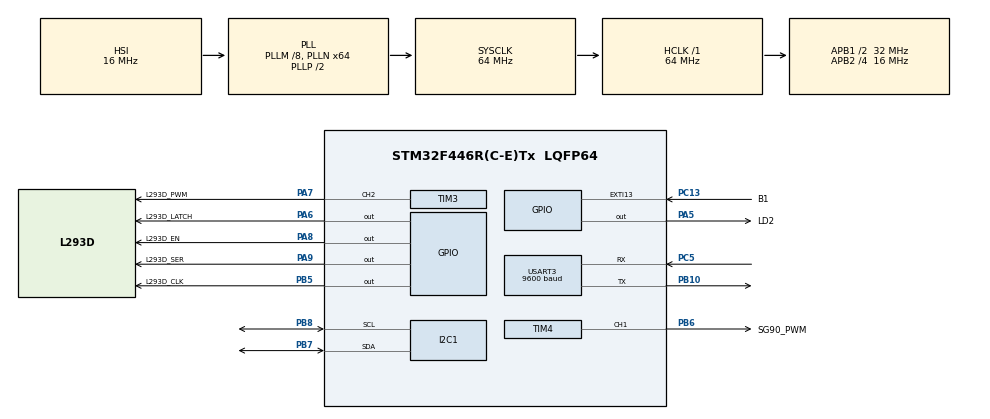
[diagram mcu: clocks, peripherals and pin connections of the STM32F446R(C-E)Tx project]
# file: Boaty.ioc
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Dma.Request0=USART3_RX
Dma.USART3_RX.0.Direction=DMA_PERIPH_TO_MEMORY
Dma.USART3_RX.0.FIFOMode=DMA_FIFOMODE_DISABLE
Dma.USART3_RX.0.Instance=DMA1_Stream1
Dma.USART3_RX.0.MemDataAlignment=DMA_MDATAALIGN_BYTE
Dma.USART3_RX.0.MemInc=DMA_MINC_ENABLE
Dma.USART3_RX.0.Mode=DMA_CIRCULAR
Dma.USART3_RX.0.PeriphDataAlignment=DMA_PDATAALIGN_BYTE
Dma.USART3_RX.0.PeriphInc=DMA_PINC_DISABLE
Dma.USART3_RX.0.Priority=DMA_PRIORITY_LOW
Mcu.Family=STM32F4
Mcu.Name=STM32F446R(C-E)Tx
Mcu.Package=LQFP64
NVIC.DMA1_Stream1_IRQn=true\:0\:0\:false\:false\:true\:false\:true\:true
NVIC.EXTI15_10_IRQn=true\:0\:0\:false\:false\:true\:true\:true\:true
NVIC.PriorityGroup=NVIC_PRIORITYGROUP_4
NVIC.TIM3_IRQn=true\:0\:0\:false\:false\:true\:true\:true\:true
NVIC.USART3_IRQn=true\:0\:0\:false\:false\:true\:true\:true\:true
PA13.Mode=Serial_Wire
PA13.Signal=SYS_JTMS-SWDIO
PA14.Mode=Serial_Wire
PA14.Signal=SYS_JTCK-SWCLK
PA5.GPIO_Label=LD2
PA5.Signal=GPIO_Output
PA6.GPIO_Label=L293D_LATCH
PA6.Signal=GPIO_Output
PA7.GPIO_Label=L293D_PWM
PA7.Signal=S_TIM3_CH2
PA8.GPIO_Label=L293D_EN
PA8.Signal=GPIO_Output
PA9.GPIO_Label=L293D_SER
PA9.Signal=GPIO_Output
PB10.Mode=Asynchronous
PB10.Signal=USART3_TX
PB5.GPIO_Label=L293D_CLK
PB5.Signal=GPIO_Output
PB6.GPIO_Label=SG90_PWM
PB6.Signal=S_TIM4_CH1
PB7.Mode=I2C
PB7.Signal=I2C1_SDA
PB8.Mode=I2C
PB8.Signal=I2C1_SCL
PC13.GPIO_Label=B1
PC13.Signal=GPXTI13
PC5.Mode=Asynchronous
PC5.Signal=USART3_RX
ProjectManager.HeapSize=0x200
ProjectManager.StackSize=0x400
ProjectManager.TargetToolchain=STM32CubeIDE
RCC.AHBFreq_Value=64000000
RCC.APB1CLKDivider=RCC_HCLK_DIV2
RCC.APB1Freq_Value=32000000
RCC.APB1TimFreq_Value=64000000
RCC.APB2CLKDivider=RCC_HCLK_DIV4
RCC.APB2Freq_Value=16000000
RCC.APB2TimFreq_Value=32000000
RCC.CortexFreq_Value=64000000
RCC.HCLKFreq_Value=64000000
RCC.PLLM=8
RCC.PLLN=64
RCC.SYSCLKFreq_VALUE=64000000
RCC.SYSCLKSource=RCC_SYSCLKSOURCE_PLLCLK
RCC.USBFreq_Value=64000000
RCC.VCOOutputFreq_Value=128000000
SH.S_TIM3_CH2.0=TIM3_CH2,PWM Generation2 CH2
SH.S_TIM4_CH1.0=TIM4_CH1,PWM Generation1 CH1
TIM3.AutoReloadPreload=TIM_AUTORELOAD_PRELOAD_DISABLE
TIM3.Channel-PWM\ Generation2\ CH2=TIM_CHANNEL_2
TIM3.Period=999
TIM3.Prescaler=63
TIM3.Pulse-PWM\ Generation2\ CH2=0
TIM4.Channel-PWM\ Generation1\ CH1=TIM_CHANNEL_1
TIM4.Period=999
TIM4.Prescaler=1279
USART3.BaudRate=9600
USART3.VirtualMode=VM_ASYNC
VP_TIM3_VS_ClockSourceINT.Mode=Internal
VP_TIM4_VS_ClockSourceINT.Mode=Internal
board=custom

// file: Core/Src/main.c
/* USER CODE BEGIN Header */
/**
  ******************************************************************************
  * @file           : main.c
  * @brief          : Main program body
  ******************************************************************************
  * @attention
  *
  * Copyright (c) 2023 STMicroelectronics.
  * All rights reserved.
  *
  * This software is licensed under terms that can be found
 *in the LICENSE file in the root directory of this software
 *component. If no LICENSE file comes with this software, it
 *is provided AS-IS.
  *
  ******************************************************************************
  */
/* USER CODE END Header */
#include "main.h"
#include "dma.h"
#include "i2c.h"
#include "tim.h"
#include "usart.h"
#include "gpio.h"

/* USER CODE BEGIN Includes */
#include "Controllers/SystemController.h"
/* USER CODE END Includes */

void SystemClock_Config(void);

int main(void)
{

  /* MCU Configuration--------------------------------------------------------*/

  /* Reset of all peripherals, Initializes the Flash interface and the Systick. */
  HAL_Init();

  /* Configure the system clock */
  SystemClock_Config();

  /* Initialize all configured peripherals */
  MX_GPIO_Init();
  MX_DMA_Init();
  MX_TIM3_Init();
  MX_TIM4_Init();
  MX_I2C1_Init();
  MX_USART3_UART_Init();
  /* USER CODE BEGIN 2 */
  SystemController_Init();
  /* USER CODE END 2 */

  /* Infinite loop */
  while (1) {

    /* USER CODE BEGIN 3 */
    SystemController_Run();

  }
  /* USER CODE END 3 */
}

void SystemClock_Config(void)
{
  RCC_OscInitTypeDef RCC_OscInitStruct = {0};
  RCC_ClkInitTypeDef RCC_ClkInitStruct = {0};

  /** Configure the main internal regulator output voltage
  */
  __HAL_RCC_PWR_CLK_ENABLE();
  __HAL_PWR_VOLTAGESCALING_CONFIG(PWR_REGULATOR_VOLTAGE_SCALE3);

  /** Initializes the RCC Oscillators according to the specified parameters
  * in the RCC_OscInitTypeDef structure.
  */
  RCC_OscInitStruct.OscillatorType = RCC_OSCILLATORTYPE_HSI;
  RCC_OscInitStruct.HSIState = RCC_HSI_ON;
  RCC_OscInitStruct.HSICalibrationValue = RCC_HSICALIBRATION_DEFAULT;
  RCC_OscInitStruct.PLL.PLLState = RCC_PLL_ON;
  RCC_OscInitStruct.PLL.PLLSource = RCC_PLLSOURCE_HSI;
  RCC_OscInitStruct.PLL.PLLM = 8;
  RCC_OscInitStruct.PLL.PLLN = 64;
  RCC_OscInitStruct.PLL.PLLP = RCC_PLLP_DIV2;
  RCC_OscInitStruct.PLL.PLLQ = 2;
  RCC_OscInitStruct.PLL.PLLR = 2;
  if (HAL_RCC_OscConfig(&RCC_OscInitStruct) != HAL_OK)
  {
    Error_Handler();
  }

  /** Initializes the CPU, AHB and APB buses clocks
  */
  RCC_ClkInitStruct.ClockType = RCC_CLOCKTYPE_HCLK|RCC_CLOCKTYPE_SYSCLK
                              |RCC_CLOCKTYPE_PCLK1|RCC_CLOCKTYPE_PCLK2;
  RCC_ClkInitStruct.SYSCLKSource = RCC_SYSCLKSOURCE_PLLCLK;
  RCC_ClkInitStruct.AHBCLKDivider = RCC_SYSCLK_DIV1;
  RCC_ClkInitStruct.APB1CLKDivider = RCC_HCLK_DIV2;
  RCC_ClkInitStruct.APB2CLKDivider = RCC_HCLK_DIV4;

  if (HAL_RCC_ClockConfig(&RCC_ClkInitStruct, FLASH_LATENCY_2) != HAL_OK)
  {
    Error_Handler();
  }
}

void Error_Handler(void)
{
  /* USER CODE BEGIN Error_Handler_Debug */
  /* User can add his own implementation to report the HAL
     * error return state */
  __disable_irq();
  while (1) {}
  /* USER CODE END Error_Handler_Debug */
}

#ifdef  USE_FULL_ASSERT
/**
  * @brief  Reports the name of the source file and the source line number
  *         where the assert_param error has occurred.
  * @param  file: pointer to the source file name
  * @param  line: assert_param error line source number
  * @retval None
  */
void assert_failed(uint8_t *file, uint32_t line)
{
  /* USER CODE BEGIN 6 */
  /* User can add his own implementation to report the
       file name and line number, ex: printf("Wrong
       parameters value: file %s on line %d\r\n", file,
       line) */
  /* USER CODE END 6 */
}
#endif /* USE_FULL_ASSERT */
